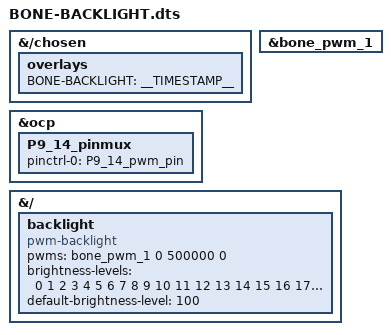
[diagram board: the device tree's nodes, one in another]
/*
 * Copyright (C) 2020 Deepak Khatri <deepaklorkhatri7@gmail.com>
 * See Cape Interface Spec page for more info on Bone Buses
 * https://elinux.org/Beagleboard:BeagleBone_cape_interface_spec
 *
 * P9.14 Backlight overlay for BBBWL/BBB/BBAI
 *
 * This program is free software; you can redistribute it and/or modify
 * it under the terms of the GNU General Public License version 2 as
 * published by the Free Software Foundation.
 */

/dts-v1/;
/plugin/;

/*
* Helper to show loaded overlays under: /proc/device-tree/chosen/overlays/
*/
&{/chosen} {
    overlays {
        BONE-BACKLIGHT = __TIMESTAMP__;
    };
};

/*
 * Update the default pinmux of the pins.
 * See these files for the phandles (&P9_* & &P8_*)
 * BeagleBoard-DeviceTrees/v4.19.x-ti-overlays/src/arm/am335x-bone-common-univ.dtsi
 * BeagleBoard-DeviceTrees/v4.19.x-ti-overlays/src/arm/am572x-bone-common-univ.dtsi
 */
&ocp {
    P9_14_pinmux { pinctrl-0 = <&P9_14_pwm_pin>; };    /* BACKLIGHT */

};

/*
 * See these files for the phandles (&bone_*) and other bone bus nodes
 * BeagleBoard-DeviceTrees/v4.19.x-ti-overlays/src/arm/bbai-bone-buses.dtsi
 * BeagleBoard-DeviceTrees/v4.19.x-ti-overlays/src/arm/bbb-bone-buses.dtsi
 */
&bone_pwm_1 {
    status = "okay";
};

&{/} {
	backlight {
		status = "okay";
		compatible = "pwm-backlight";
		pwms = <&bone_pwm_1 0 500000 0>;
		brightness-levels = <
			0  1  2  3  4  5  6  7  8  9
			10 11 12 13 14 15 16 17 18 19
			20 21 22 23 24 25 26 27 28 29
			30 31 32 33 34 35 36 37 38 39
			40 41 42 43 44 45 46 47 48 49
			50 51 52 53 54 55 56 57 58 59
			60 61 62 63 64 65 66 67 68 69
			70 71 72 73 74 75 76 77 78 79
			80 81 82 83 84 85 86 87 88 89
			90 91 92 93 94 95 96 97 98 99
			100
		>;
		default-brightness-level = <100>;
	};
};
